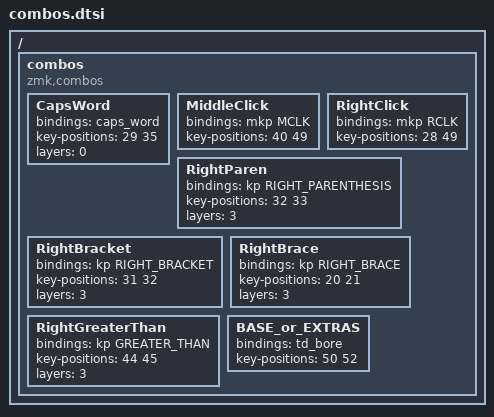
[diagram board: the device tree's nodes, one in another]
/ {
    combos {
        compatible = "zmk,combos";

        CapsWord {
            bindings = <&caps_word>;
            key-positions = <29 35>;
            layers = <0>;
        };

        MiddleClick {
            bindings = <&mkp MCLK>;
            key-positions = <40 49>;
        };

        RightClick {
            bindings = <&mkp RCLK>;
            key-positions = <28 49>;
        };

        RightParen {
            bindings = <&kp RIGHT_PARENTHESIS>;
            key-positions = <32 33>;
            layers = <3>;
        };

        RightBracket {
            bindings = <&kp RIGHT_BRACKET>;
            key-positions = <31 32>;
            layers = <3>;
        };

        RightBrace {
            bindings = <&kp RIGHT_BRACE>;
            key-positions = <20 21>;
            layers = <3>;
        };

        RightGreaterThan {
            bindings = <&kp GREATER_THAN>;
            key-positions = <44 45>;
            layers = <3>;
        };

        BASE_or_EXTRAS {
            bindings = <&td_bore>;
            key-positions = <50 52>;
        };

        // GameLayer {
        //     bindings = <&tog 4>;
        //     key-positions = <8 9>;
        // };

        // PhotoLayer {
        //     bindings = <&tog 5>;
        //     key-positions = <2 3>;
        // };
    };
};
